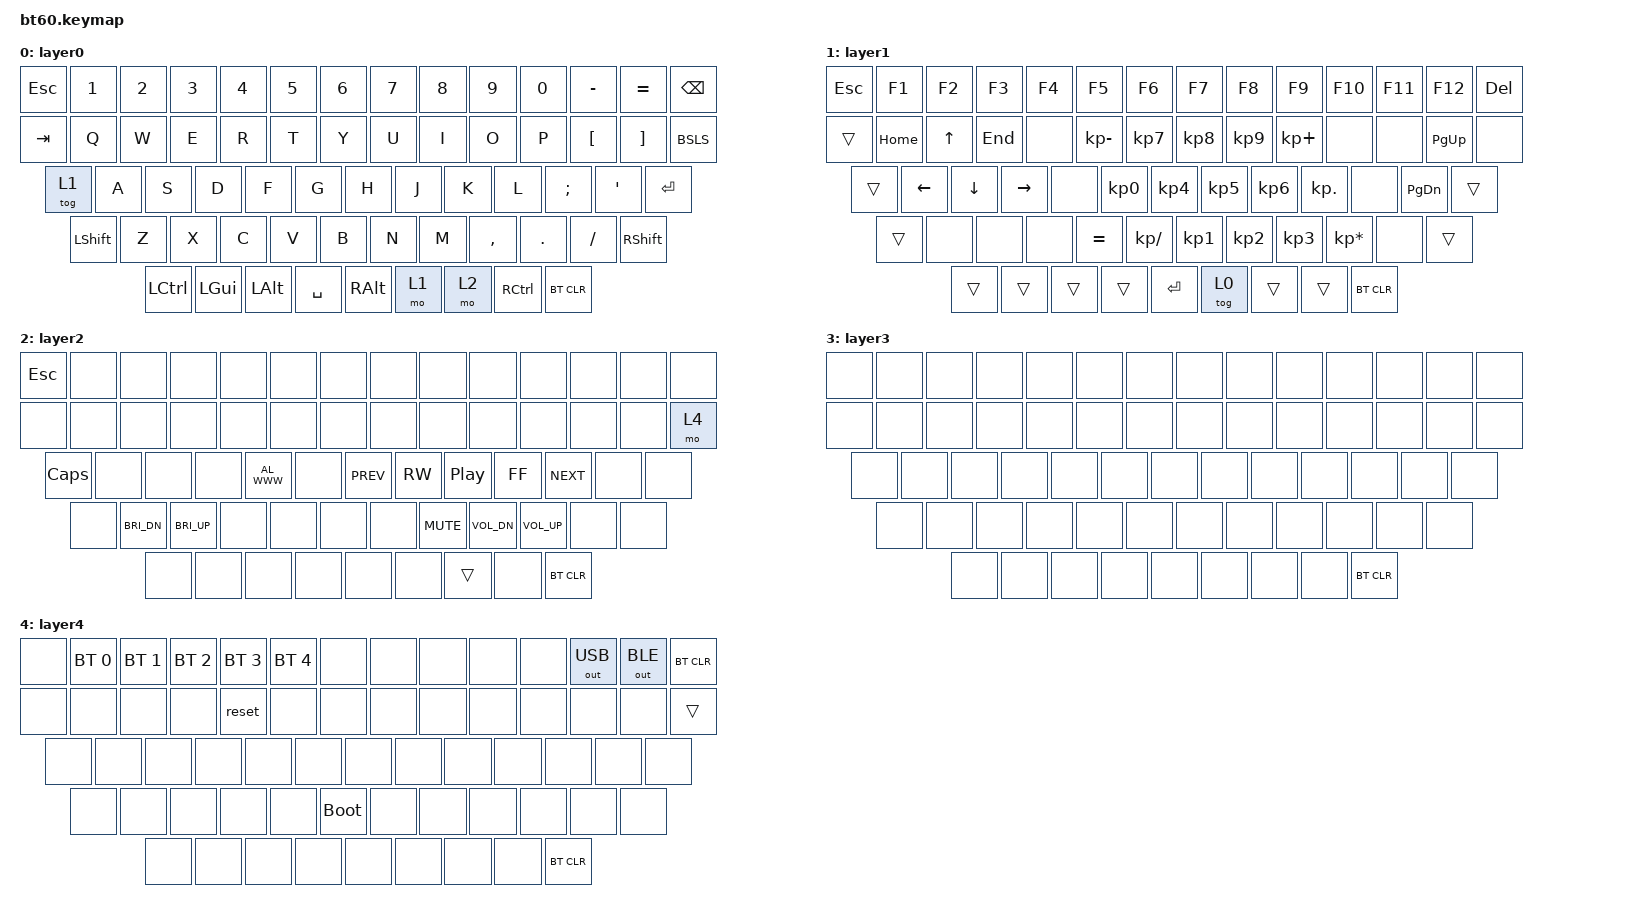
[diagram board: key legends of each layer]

#include <behaviors.dtsi>
#include <dt-bindings/zmk/keys.h>
#include <dt-bindings/zmk/bt.h>

/ {
	keymap {
		compatible = "zmk,keymap";
		layer0 {
			bindings = <
				&kp ESC &kp 1 &kp 2 &kp 3 &kp 4 &kp 5 &kp 6 &kp 7 &kp 8 &kp 9 &kp 0 &kp MINUS &kp EQUAL &kp BSPC
				&kp TAB &kp Q &kp W &kp E &kp R &kp T &kp Y &kp U &kp I &kp O &kp P &kp LBKT &kp RBKT &kp BSLS
				&tog 1 &kp A &kp S &kp D &kp F &kp G &kp H &kp J &kp K &kp L &kp SEMI &kp SQT &kp ENTER
				&kp LSHFT &kp Z &kp X &kp C &kp V &kp B &kp N &kp M &kp COMMA &kp DOT &kp SLASH &kp RSHFT
				&kp LCTRL &kp LGUI &kp LALT &kp SPACE &kp RALT &mo 1 &mo 2 &kp RCTRL &bt BT_CLR
			>;

			sensor-bindings = <&inc_dec_kp C_VOL_UP C_VOL_DN>;
		};

		layer1 {
			bindings = <
				&kp ESC &kp F1 &kp F2 &kp F3 &kp F4 &kp F5 &kp F6 &kp F7 &kp F8 &kp F9 &kp F10 &kp F11 &kp F12 &kp DEL
				&trans &kp HOME &kp UP &kp END &none &kp KP_MINUS &kp KP_N7 &kp KP_N8 &kp KP_N9 &kp KP_PLUS &none &none &kp PAGE_UP &none
				&trans &kp LEFT &kp DOWN &kp RIGHT &none &kp KP_N0 &kp KP_N4 &kp KP_N5 &kp KP_N6 &kp KP_DOT &none &kp PAGE_DOWN &trans
				&trans &none &none &none &kp EQUAL &kp KP_SLASH &kp KP_N1 &kp KP_N2 &kp KP_N3 &kp KP_ASTERISK &none &trans
				&trans &trans &trans &trans &kp ENTER &tog 0 &trans &trans &bt BT_CLR
			>;

			sensor-bindings = <&inc_dec_kp C_VOL_UP C_VOL_DN>;
		};

		layer2 {
			bindings = <
				&kp ESC &none &none &none &none &none &none &none &none &none &none &none &none &none
				&none &none &none &none &none &none &none &none &none &none &none &none &none &mo 4
				&kp CAPS &none &none &none &kp C_AL_WWW &none &kp C_PREV &kp C_RW &kp C_PP &kp C_FF &kp C_NEXT &none &none
				&none &kp C_BRI_DN &kp C_BRI_UP &none &none &none &none &kp C_MUTE &kp C_VOL_DN &kp C_VOL_UP &none &none
				&none &none &none &none &none &none &trans &none &bt BT_CLR
			>;

			sensor-bindings = <&inc_dec_kp C_VOL_UP C_VOL_DN>;
		};

		layer3 {
			bindings = <
				&none &none &none &none &none &none &none &none &none &none &none &none &none &none &none &none &none &none &none &none &none &none &none &none &none &none &none &none &none &none &none &none &none &none &none &none &none &none &none &none &none &none &none &none &none &none &none &none &none &none &none &none &none &none &none &none &none &none &none &none &none  &bt BT_CLR
			>;

			sensor-bindings = <&inc_dec_kp C_VOL_UP C_VOL_DN>;
		};

		layer4 {
			bindings = <
				&none &bt BT_SEL 0 &bt BT_SEL 1 &bt BT_SEL 2 &bt BT_SEL 3 &bt BT_SEL 4 &none &none &none &none &none &out OUT_USB &out OUT_BLE &bt BT_CLR
				&none &none &none &none &reset &none &none &none &none &none &none &none &none &trans
				&none &none &none &none &none &none &none &none &none &none &none &none &none
				&none &none &none &none &none &bootloader &none &none &none &none &none &none
				&none &none &none &none &none &none &none &none &bt BT_CLR
			>;

			sensor-bindings = <&inc_dec_kp C_VOL_UP C_VOL_DN>;
		};


	};
};
